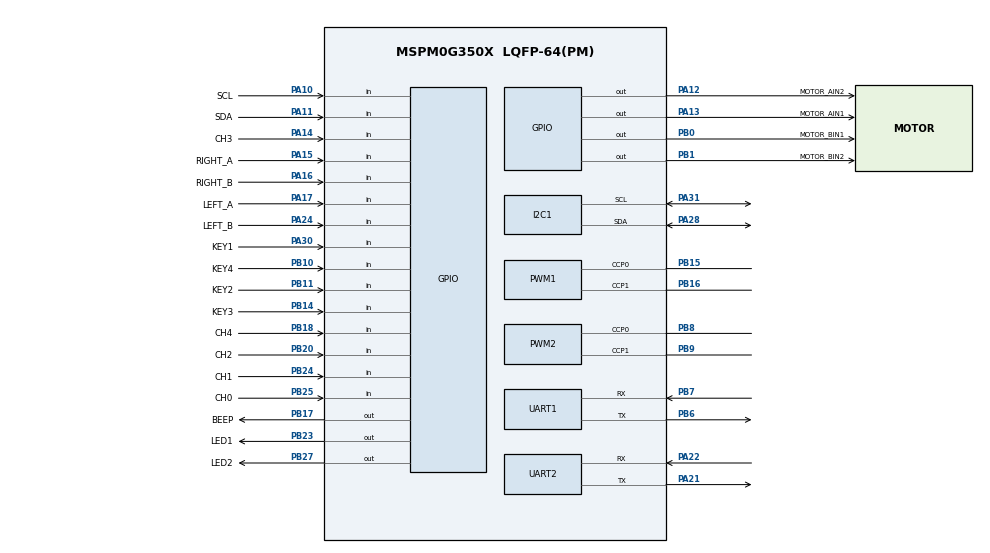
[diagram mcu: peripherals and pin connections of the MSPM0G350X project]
/**
 * @cliArgs --device "MSPM0G350X" --part "Default" --package "LQFP-64(PM)" --product "mspm0_sdk@2.10.00.04"
 * @versions {"tool":"1.26.2+4477"}
 */

/**
 * Import the modules used in this configuration.
 */
const Board   = scripting.addModule("/ti/driverlib/Board");
const GPIO    = scripting.addModule("/ti/driverlib/GPIO", {}, false);
const GPIO1   = GPIO.addInstance();
const GPIO2   = GPIO.addInstance();
const GPIO3   = GPIO.addInstance();
const GPIO4   = GPIO.addInstance();
const GPIO5   = GPIO.addInstance();
const I2C     = scripting.addModule("/ti/driverlib/I2C", {}, false);
const I2C1    = I2C.addInstance();
const PWM     = scripting.addModule("/ti/driverlib/PWM", {}, false);
const PWM1    = PWM.addInstance();
const PWM2    = PWM.addInstance();
const SYSTICK = scripting.addModule("/ti/driverlib/SYSTICK");
const UART    = scripting.addModule("/ti/driverlib/UART", {}, false);
const UART1   = UART.addInstance();
const UART2   = UART.addInstance();

/**
 * Write custom configuration values to the imported modules.
 */

GPIO1.$name                          = "BOARD_OUTPUTS";
GPIO1.associatedPins.create(7);
GPIO1.associatedPins[0].$name        = "LED1";
GPIO1.associatedPins[0].assignedPort = "PORTB";
GPIO1.associatedPins[0].assignedPin  = "23";
GPIO1.associatedPins[0].pin.$assign  = "PB23";
GPIO1.associatedPins[1].$name        = "LED2";
GPIO1.associatedPins[1].pin.$assign  = "PB27";
GPIO1.associatedPins[2].$name        = "BEEP";
GPIO1.associatedPins[2].initialValue = "SET";
GPIO1.associatedPins[2].pin.$assign  = "PB17";
GPIO1.associatedPins[3].$name        = "MOTOR_AIN1";
GPIO1.associatedPins[3].pin.$assign  = "PA13";
GPIO1.associatedPins[4].$name        = "MOTOR_AIN2";
GPIO1.associatedPins[4].pin.$assign  = "PA12";
GPIO1.associatedPins[5].$name        = "MOTOR_BIN1";
GPIO1.associatedPins[5].pin.$assign  = "PB0";
GPIO1.associatedPins[6].$name        = "MOTOR_BIN2";
GPIO1.associatedPins[6].pin.$assign  = "PB1";

GPIO2.$name                         = "MPU_GPIO";
GPIO2.associatedPins.create(2);
GPIO2.associatedPins[0].$name       = "SCL";
GPIO2.associatedPins[0].direction   = "INPUT";
GPIO2.associatedPins[0].pin.$assign = "PA10";
GPIO2.associatedPins[1].$name       = "SDA";
GPIO2.associatedPins[1].direction   = "INPUT";
GPIO2.associatedPins[1].pin.$assign = "PA11";

GPIO3.$name                         = "GRAY_INPUTS";
GPIO3.associatedPins.create(5);
GPIO3.associatedPins[0].$name       = "CH0";
GPIO3.associatedPins[0].direction   = "INPUT";
GPIO3.associatedPins[0].pin.$assign = "PB25";
GPIO3.associatedPins[1].$name       = "CH1";
GPIO3.associatedPins[1].direction   = "INPUT";
GPIO3.associatedPins[1].pin.$assign = "PB24";
GPIO3.associatedPins[2].$name       = "CH2";
GPIO3.associatedPins[2].direction   = "INPUT";
GPIO3.associatedPins[2].pin.$assign = "PB20";
GPIO3.associatedPins[3].$name       = "CH3";
GPIO3.associatedPins[3].direction   = "INPUT";
GPIO3.associatedPins[3].pin.$assign = "PA14";
GPIO3.associatedPins[4].$name       = "CH4";
GPIO3.associatedPins[4].direction   = "INPUT";
GPIO3.associatedPins[4].pin.$assign = "PB18";

GPIO4.$name                         = "BUTTON_INPUTS";
GPIO4.associatedPins.create(4);
GPIO4.associatedPins[0].$name       = "KEY1";
GPIO4.associatedPins[0].direction   = "INPUT";
GPIO4.associatedPins[0].pin.$assign = "PA30";
GPIO4.associatedPins[1].$name       = "KEY2";
GPIO4.associatedPins[1].direction   = "INPUT";
GPIO4.associatedPins[1].pin.$assign = "PB11";
GPIO4.associatedPins[2].$name       = "KEY3";
GPIO4.associatedPins[2].direction   = "INPUT";
GPIO4.associatedPins[2].pin.$assign = "PB14";
GPIO4.associatedPins[3].$name       = "KEY4";
GPIO4.associatedPins[3].direction   = "INPUT";
GPIO4.associatedPins[3].pin.$assign = "PB10";

GPIO5.$name                                 = "ENCODER_INPUTS";
GPIO5.associatedPins.create(4);
GPIO5.associatedPins[0].$name               = "RIGHT_A";
GPIO5.associatedPins[0].direction           = "INPUT";
GPIO5.associatedPins[0].internalResistor    = "PULL_UP";
GPIO5.associatedPins[0].interruptEn         = true;
GPIO5.associatedPins[0].polarity            = "RISE_FALL";
GPIO5.associatedPins[0].assignedPortSegment = "Lower";
GPIO5.associatedPins[0].pin.$assign         = "PA15";
GPIO5.associatedPins[1].$name               = "RIGHT_B";
GPIO5.associatedPins[1].direction           = "INPUT";
GPIO5.associatedPins[1].internalResistor    = "PULL_UP";
GPIO5.associatedPins[1].interruptEn         = true;
GPIO5.associatedPins[1].polarity            = "RISE_FALL";
GPIO5.associatedPins[1].assignedPortSegment = "Upper";
GPIO5.associatedPins[1].pin.$assign         = "PA16";
GPIO5.associatedPins[2].$name               = "LEFT_A";
GPIO5.associatedPins[2].direction           = "INPUT";
GPIO5.associatedPins[2].internalResistor    = "PULL_UP";
GPIO5.associatedPins[2].interruptEn         = true;
GPIO5.associatedPins[2].polarity            = "RISE_FALL";
GPIO5.associatedPins[2].assignedPortSegment = "Upper";
GPIO5.associatedPins[2].pin.$assign         = "PA17";
GPIO5.associatedPins[3].$name               = "LEFT_B";
GPIO5.associatedPins[3].direction           = "INPUT";
GPIO5.associatedPins[3].internalResistor    = "PULL_UP";
GPIO5.associatedPins[3].interruptEn         = true;
GPIO5.associatedPins[3].polarity            = "RISE_FALL";
GPIO5.associatedPins[3].pin.$assign         = "PA24";

I2C1.$name                             = "OLED_I2C";
I2C1.basicEnableController             = true;
I2C1.basicControllerBusSpeed           = 400000;
I2C1.advAnalogGlitchFilter             = "DISABLED";
I2C1.peripheral.$assign                = "I2C0";
I2C1.peripheral.sdaPin.$assign         = "PA28";
I2C1.peripheral.sclPin.$assign         = "PA31";
I2C1.sdaPinConfig.hideOutputInversion  = scripting.forceWrite(false);
I2C1.sdaPinConfig.onlyInternalResistor = scripting.forceWrite(false);
I2C1.sdaPinConfig.passedPeripheralType = scripting.forceWrite("Digital");
I2C1.sdaPinConfig.$name                = "ti_driverlib_gpio_GPIOPinGeneric2";
I2C1.sclPinConfig.hideOutputInversion  = scripting.forceWrite(false);
I2C1.sclPinConfig.onlyInternalResistor = scripting.forceWrite(false);
I2C1.sclPinConfig.passedPeripheralType = scripting.forceWrite("Digital");
I2C1.sclPinConfig.$name                = "ti_driverlib_gpio_GPIOPinGeneric3";

PWM1.$name                              = "MOTOR_PWM";
PWM1.timerCount                         = 1600;
PWM1.peripheral.$assign                 = "TIMG8";
PWM1.peripheral.ccp0Pin.$assign         = "PB15";
PWM1.peripheral.ccp1Pin.$assign         = "PB16";
PWM1.PWM_CHANNEL_0.$name                = "MOTOR_RIGHT";
PWM1.PWM_CHANNEL_1.$name                = "MOTOR_LEFT";
PWM1.ccp0PinConfig.direction            = scripting.forceWrite("OUTPUT");
PWM1.ccp0PinConfig.hideOutputInversion  = scripting.forceWrite(false);
PWM1.ccp0PinConfig.onlyInternalResistor = scripting.forceWrite(false);
PWM1.ccp0PinConfig.passedPeripheralType = scripting.forceWrite("Digital");
PWM1.ccp0PinConfig.$name                = "ti_driverlib_gpio_GPIOPinGeneric4";
PWM1.ccp1PinConfig.direction            = scripting.forceWrite("OUTPUT");
PWM1.ccp1PinConfig.hideOutputInversion  = scripting.forceWrite(false);
PWM1.ccp1PinConfig.onlyInternalResistor = scripting.forceWrite(false);
PWM1.ccp1PinConfig.passedPeripheralType = scripting.forceWrite("Digital");
PWM1.ccp1PinConfig.$name                = "ti_driverlib_gpio_GPIOPinGeneric5";

PWM2.$name                              = "SERVO_PWM";
PWM2.clockPrescale                      = 32;
PWM2.timerCount                         = 20000;
PWM2.peripheral.$assign                 = "TIMA0";
PWM2.peripheral.ccp0Pin.$assign         = "PB8";
PWM2.peripheral.ccp1Pin.$assign         = "PB9";
PWM2.PWM_CHANNEL_0.$name                = "SERVO_HORIZONTAL";
PWM2.PWM_CHANNEL_0.dutyCycle            = 7.5;
PWM2.PWM_CHANNEL_1.$name                = "SERVO_VERTICAL";
PWM2.PWM_CHANNEL_1.dutyCycle            = 7.5;
PWM2.ccp0PinConfig.direction            = scripting.forceWrite("OUTPUT");
PWM2.ccp0PinConfig.hideOutputInversion  = scripting.forceWrite(false);
PWM2.ccp0PinConfig.onlyInternalResistor = scripting.forceWrite(false);
PWM2.ccp0PinConfig.passedPeripheralType = scripting.forceWrite("Digital");
PWM2.ccp0PinConfig.$name                = "ti_driverlib_gpio_GPIOPinGeneric6";
PWM2.ccp1PinConfig.direction            = scripting.forceWrite("OUTPUT");
PWM2.ccp1PinConfig.hideOutputInversion  = scripting.forceWrite(false);
PWM2.ccp1PinConfig.onlyInternalResistor = scripting.forceWrite(false);
PWM2.ccp1PinConfig.passedPeripheralType = scripting.forceWrite("Digital");
PWM2.ccp1PinConfig.$name                = "ti_driverlib_gpio_GPIOPinGeneric7";

const SYSCTL                 = scripting.addModule("/ti/driverlib/SYSCTL", {}, false);
SYSCTL.forceDefaultClkConfig = true;
SYSCTL.clockTreeEn           = true;

SYSTICK.period          = 320000;
SYSTICK.periodEnable    = true;
SYSTICK.systickEnable   = true;
SYSTICK.interruptEnable = true;

UART1.$name                            = "BLUETOOTH_UART";
UART1.rxFifoThreshold                  = "DL_UART_RX_FIFO_LEVEL_ONE_ENTRY";
UART1.enableDMARX                      = false;
UART1.enableDMATX                      = false;
UART1.enabledInterrupts                = ["RX"];
UART1.peripheral.$assign               = "UART1";
UART1.peripheral.rxPin.$assign         = "PB7";
UART1.peripheral.txPin.$assign         = "PB6";
UART1.txPinConfig.direction            = scripting.forceWrite("OUTPUT");
UART1.txPinConfig.hideOutputInversion  = scripting.forceWrite(false);
UART1.txPinConfig.onlyInternalResistor = scripting.forceWrite(false);
UART1.txPinConfig.passedPeripheralType = scripting.forceWrite("Digital");
UART1.txPinConfig.$name                = "ti_driverlib_gpio_GPIOPinGeneric0";
UART1.rxPinConfig.hideOutputInversion  = scripting.forceWrite(false);
UART1.rxPinConfig.onlyInternalResistor = scripting.forceWrite(false);
UART1.rxPinConfig.passedPeripheralType = scripting.forceWrite("Digital");
UART1.rxPinConfig.$name                = "ti_driverlib_gpio_GPIOPinGeneric1";

UART2.$name                            = "K230";
UART2.targetBaudRate                   = 115200;
UART2.enabledInterrupts                = ["RX"];
UART2.peripheral.rxPin.$assign         = "PA22";
UART2.peripheral.txPin.$assign         = "PA21";
UART2.txPinConfig.$name                = "ti_driverlib_gpio_GPIOPinGeneric8";
UART2.txPinConfig.direction            = scripting.forceWrite("OUTPUT");
UART2.txPinConfig.hideOutputInversion  = scripting.forceWrite(false);
UART2.txPinConfig.onlyInternalResistor = scripting.forceWrite(false);
UART2.txPinConfig.passedPeripheralType = scripting.forceWrite("Digital");
UART2.txPinConfig.enableConfig         = true;
UART2.rxPinConfig.$name                = "ti_driverlib_gpio_GPIOPinGeneric9";
UART2.rxPinConfig.hideOutputInversion  = scripting.forceWrite(false);
UART2.rxPinConfig.onlyInternalResistor = scripting.forceWrite(false);
UART2.rxPinConfig.passedPeripheralType = scripting.forceWrite("Digital");

/**
 * Pinmux solution for unlocked pins/peripherals. This ensures that minor changes to the automatic solver in a future
 * version of the tool will not impact the pinmux you originally saw.  These lines can be completely deleted in order to
 * re-solve from scratch.
 */
Board.peripheral.$suggestSolution          = "DEBUGSS";
Board.peripheral.swclkPin.$suggestSolution = "PA20";
Board.peripheral.swdioPin.$suggestSolution = "PA19";
UART2.peripheral.$suggestSolution          = "UART2";
